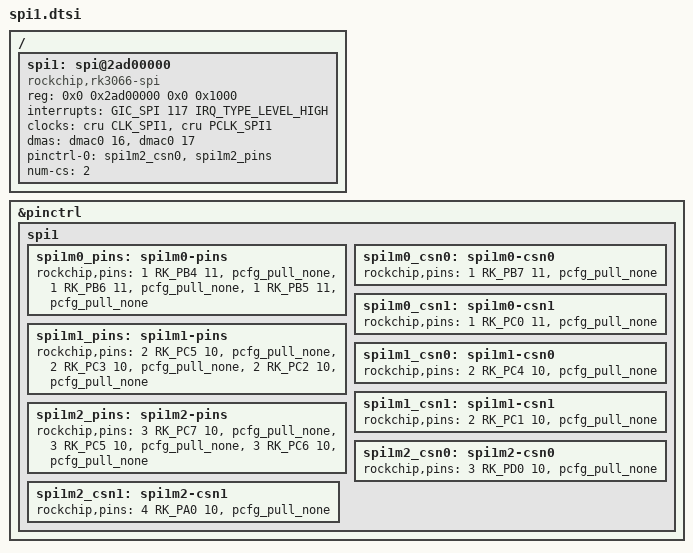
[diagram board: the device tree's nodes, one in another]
/ {
	spi1: spi@2ad00000 {
		compatible = "rockchip,rk3066-spi";
		reg = <0x0 0x2ad00000 0x0 0x1000>;
		interrupts = <GIC_SPI 117 IRQ_TYPE_LEVEL_HIGH>;
		#address-cells = <1>;
		#size-cells = <0>;
		clocks = <&cru CLK_SPI1>, <&cru PCLK_SPI1>;
		clock-names = "spiclk", "apb_pclk";
		dmas = <&dmac0 16>, <&dmac0 17>;
		dma-names = "tx", "rx";
		pinctrl-names = "default";
		pinctrl-0 = <&spi1m0_csn0 &spi1m0_pins>;
		num-cs = <2>;
		status = "disabled";
	};
};

&spi1{
	status = "okay";
	pinctrl-0 = <&spi1m2_csn0 &spi1m2_pins>;
};

&pinctrl {
	spi1 {
			/omit-if-no-ref/
			spi1m0_pins: spi1m0-pins {
				rockchip,pins =
					/* spi1_clk_m0 */
					<1 RK_PB4 11 &pcfg_pull_none>,
					/* spi1_miso_m0 */
					<1 RK_PB6 11 &pcfg_pull_none>,
					/* spi1_mosi_m0 */
					<1 RK_PB5 11 &pcfg_pull_none>;
			};

			/omit-if-no-ref/
			spi1m0_csn0: spi1m0-csn0 {
				rockchip,pins =
					/* spi1m0_csn0 */
					<1 RK_PB7 11 &pcfg_pull_none>;
			};
			/omit-if-no-ref/
			spi1m0_csn1: spi1m0-csn1 {
				rockchip,pins =
					/* spi1m0_csn1 */
					<1 RK_PC0 11 &pcfg_pull_none>;
			};

			/omit-if-no-ref/
			spi1m1_pins: spi1m1-pins {
				rockchip,pins =
					/* spi1_clk_m1 */
					<2 RK_PC5 10 &pcfg_pull_none>,
					/* spi1_miso_m1 */
					<2 RK_PC3 10 &pcfg_pull_none>,
					/* spi1_mosi_m1 */
					<2 RK_PC2 10 &pcfg_pull_none>;
			};

			/omit-if-no-ref/
			spi1m1_csn0: spi1m1-csn0 {
				rockchip,pins =
					/* spi1m1_csn0 */
					<2 RK_PC4 10 &pcfg_pull_none>;
			};
			/omit-if-no-ref/
			spi1m1_csn1: spi1m1-csn1 {
				rockchip,pins =
					/* spi1m1_csn1 */
					<2 RK_PC1 10 &pcfg_pull_none>;
			};

			/omit-if-no-ref/
			spi1m2_pins: spi1m2-pins {
				rockchip,pins =
					/* spi1_clk_m2 */
					<3 RK_PC7 10 &pcfg_pull_none>,
					/* spi1_miso_m2 */
					<3 RK_PC5 10 &pcfg_pull_none>,
					/* spi1_mosi_m2 */
					<3 RK_PC6 10 &pcfg_pull_none>;
			};

			/omit-if-no-ref/
			spi1m2_csn0: spi1m2-csn0 {
				rockchip,pins =
					/* spi1m2_csn0 */
					<3 RK_PD0 10 &pcfg_pull_none>;
			};
			/omit-if-no-ref/
			spi1m2_csn1: spi1m2-csn1 {
				rockchip,pins =
					/* spi1m2_csn1 */
					<4 RK_PA0 10 &pcfg_pull_none>;
			};
		};
};
